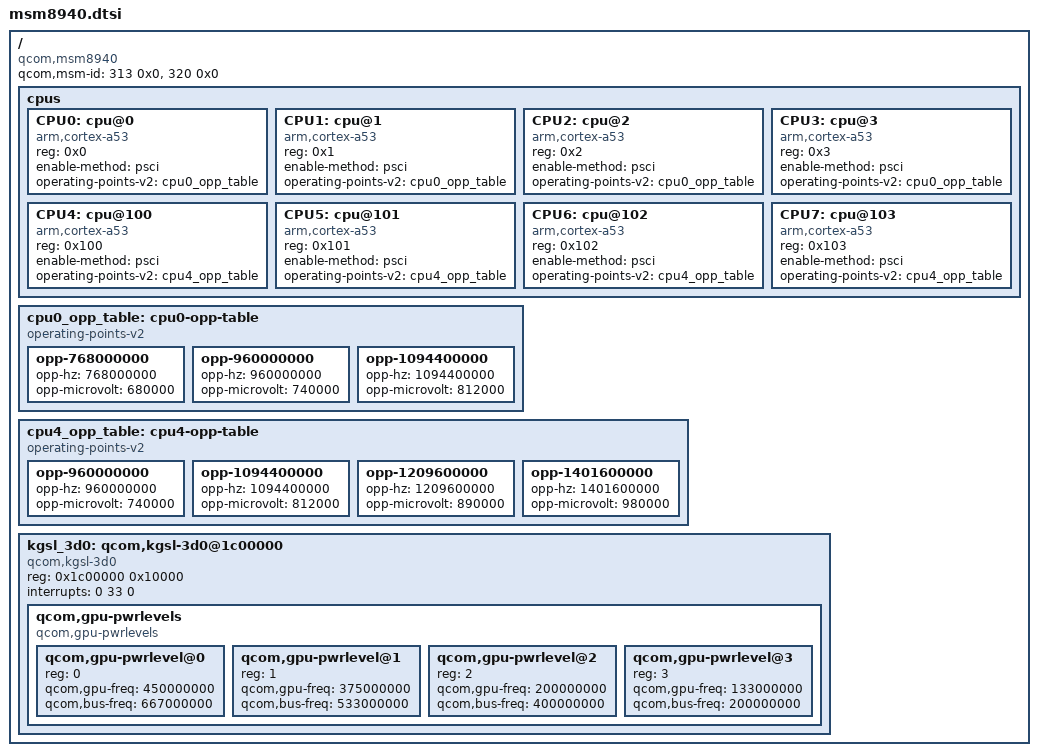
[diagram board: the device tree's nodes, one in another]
// SPDX-License-Identifier: GPL-2.0
/*
 * Qualcomm MSM8940 / MSM8937 Device Tree Source
 * Reference: Xiaomi Redmi 4X (Santoni) - Baseline Minimum Qualcomm
 * Source: MiCode/Xiaomi_Kernel_OpenSource (santoni-n-oss)
 */

/ {
	compatible = "qcom,msm8940", "qcom,msm8937";
	qcom,msm-id = <313 0x0>, <320 0x0>;

	cpus {
		#address-cells = <1>;
		#size-cells = <0>;

		/* Little Cluster (Cores 0-3) */
		CPU0: cpu@0 {
			device_type = "cpu";
			compatible = "arm,cortex-a53";
			reg = <0x0>;
			enable-method = "psci";
			operating-points-v2 = <&cpu0_opp_table>;
		};
		CPU1: cpu@1 {
			device_type = "cpu";
			compatible = "arm,cortex-a53";
			reg = <0x1>;
			enable-method = "psci";
			operating-points-v2 = <&cpu0_opp_table>;
		};
		CPU2: cpu@2 {
			device_type = "cpu";
			compatible = "arm,cortex-a53";
			reg = <0x2>;
			enable-method = "psci";
			operating-points-v2 = <&cpu0_opp_table>;
		};
		CPU3: cpu@3 {
			device_type = "cpu";
			compatible = "arm,cortex-a53";
			reg = <0x3>;
			enable-method = "psci";
			operating-points-v2 = <&cpu0_opp_table>;
		};

		/* Big/Performance Cluster (Cores 4-7) */
		CPU4: cpu@100 {
			device_type = "cpu";
			compatible = "arm,cortex-a53";
			reg = <0x100>;
			enable-method = "psci";
			operating-points-v2 = <&cpu4_opp_table>;
		};
		CPU5: cpu@101 {
			device_type = "cpu";
			compatible = "arm,cortex-a53";
			reg = <0x101>;
			enable-method = "psci";
			operating-points-v2 = <&cpu4_opp_table>;
		};
		CPU6: cpu@102 {
			device_type = "cpu";
			compatible = "arm,cortex-a53";
			reg = <0x102>;
			enable-method = "psci";
			operating-points-v2 = <&cpu4_opp_table>;
		};
		CPU7: cpu@103 {
			device_type = "cpu";
			compatible = "arm,cortex-a53";
			reg = <0x103>;
			enable-method = "psci";
			operating-points-v2 = <&cpu4_opp_table>;
		};
	};

	cpu0_opp_table: cpu0-opp-table {
		compatible = "operating-points-v2";
		opp-768000000  { opp-hz = /bits/ 64 <768000000>;  opp-microvolt = <680000>; };
		opp-960000000  { opp-hz = /bits/ 64 <960000000>;  opp-microvolt = <740000>; };
		opp-1094400000 { opp-hz = /bits/ 64 <1094400000>; opp-microvolt = <812000>; };
	};

	cpu4_opp_table: cpu4-opp-table {
		compatible = "operating-points-v2";
		opp-960000000  { opp-hz = /bits/ 64 <960000000>;  opp-microvolt = <740000>; };
		opp-1094400000 { opp-hz = /bits/ 64 <1094400000>; opp-microvolt = <812000>; };
		opp-1209600000 { opp-hz = /bits/ 64 <1209600000>; opp-microvolt = <890000>; };
		opp-1401600000 { opp-hz = /bits/ 64 <1401600000>; opp-microvolt = <980000>; };
	};

	/* Adreno 505 GPU Node */
	kgsl_3d0: qcom,kgsl-3d0@1c00000 {
		compatible = "qcom,kgsl-3d0", "qcom,kgsl-3d";
		reg = <0x1c00000 0x10000>;
		interrupts = <0 33 0>;
		qcom,gpu-pwrlevels {
			#address-cells = <1>;
			#size-cells = <0>;
			compatible = "qcom,gpu-pwrlevels";

			qcom,gpu-pwrlevel@0 {
				reg = <0>;
				qcom,gpu-freq = <450000000>;
				qcom,bus-freq = <667000000>;
			};
			qcom,gpu-pwrlevel@1 {
				reg = <1>;
				qcom,gpu-freq = <375000000>;
				qcom,bus-freq = <533000000>;
			};
			qcom,gpu-pwrlevel@2 {
				reg = <2>;
				qcom,gpu-freq = <200000000>;
				qcom,bus-freq = <400000000>;
			};
			qcom,gpu-pwrlevel@3 {
				reg = <3>;
				qcom,gpu-freq = <133000000>;
				qcom,bus-freq = <200000000>;
			};
		};
	};
};
